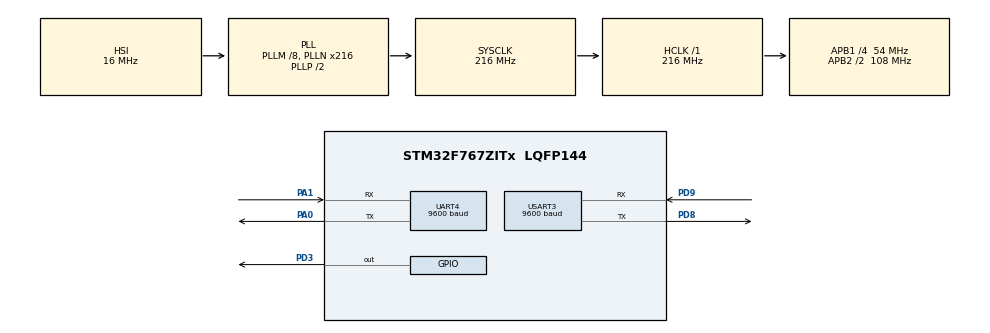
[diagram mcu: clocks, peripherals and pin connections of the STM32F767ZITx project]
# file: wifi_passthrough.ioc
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Mcu.Family=STM32F7
Mcu.Name=STM32F767ZITx
Mcu.Package=LQFP144
NVIC.PriorityGroup=NVIC_PRIORITYGROUP_4
NVIC.UART4_IRQn=true\:0\:0\:false\:false\:true\:true\:true
NVIC.USART3_IRQn=true\:0\:0\:false\:false\:true\:true\:true
PA0/WKUP.Mode=Asynchronous
PA0/WKUP.Signal=UART4_TX
PA1.Mode=Asynchronous
PA1.Signal=UART4_RX
PD3.Signal=GPIO_Output
PD8.Mode=Asynchronous
PD8.Signal=USART3_TX
PD9.Mode=Asynchronous
PD9.Signal=USART3_RX
ProjectManager.HeapSize=0x200
ProjectManager.StackSize=0x400
ProjectManager.TargetToolchain=MDK-ARM V5
RCC.48MHZClocksFreq_Value=24000000
RCC.AHBFreq_Value=216000000
RCC.APB1CLKDivider=RCC_HCLK_DIV4
RCC.APB1Freq_Value=54000000
RCC.APB1TimFreq_Value=108000000
RCC.APB2CLKDivider=RCC_HCLK_DIV2
RCC.APB2Freq_Value=108000000
RCC.APB2TimFreq_Value=216000000
RCC.CortexFreq_Value=216000000
RCC.HCLKFreq_Value=216000000
RCC.HSE_VALUE=16000000
RCC.HSI_VALUE=16000000
RCC.LSE_VALUE=32768
RCC.PLLM=8
RCC.PLLMUL=RCC_PLL_MUL9
RCC.PLLN=216
RCC.PRESCALERUSB=RCC_USBCLKSOURCE_PLL_DIV1_5
RCC.SYSCLKFreq_VALUE=216000000
RCC.SYSCLKSource=RCC_SYSCLKSOURCE_PLLCLK
RCC.SYSCLKSourceVirtual=RCC_SYSCLKSOURCE_PLLCLK
RCC.USBFreq_Value=216000000
RCC.VCOOutputFreq_Value=432000000
UART4.BaudRate=9600
USART3.BaudRate=9600
USART3.VirtualMode-Asynchronous=VM_ASYNC
board=NUCLEO-F767ZI

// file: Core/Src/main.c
/* USER CODE BEGIN Header */
/**
  ******************************************************************************
  * @file           : main.c
  * @brief          : Main program body
  ******************************************************************************
  * @attention
  *
  * <h2><center>&copy; Copyright (c) 2020 STMicroelectronics.
  * All rights reserved.</center></h2>
  *
  * This software component is licensed by ST under BSD 3-Clause license,
  * the "License"; You may not use this file except in compliance with the
  * License. You may obtain a copy of the License at:
  *                        opensource.org/licenses/BSD-3-Clause
  *
  ******************************************************************************
  */
/* USER CODE END Header */

#include "main.h"
#include "usart.h"
#include "gpio.h"

void SystemClock_Config(void);

int main(void)
{

  /* MCU Configuration--------------------------------------------------------*/

  /* Reset of all peripherals, Initializes the Flash interface and the Systick. */
  HAL_Init();

  /* Configure the system clock */
  SystemClock_Config();

  /* Initialize all configured peripherals */
  MX_GPIO_Init();
  MX_UART4_Init();
  MX_USART3_UART_Init();
  /* USER CODE BEGIN 2 */

	HAL_GPIO_WritePin(GPIOD, GPIO_PIN_3, GPIO_PIN_RESET);

	HAL_UART_Receive_IT(&huart3, &buf3, 1);
	HAL_UART_Receive_IT(&huart4, &buf4, 1);

	HAL_Delay(200);
	HAL_GPIO_WritePin(GPIOD, GPIO_PIN_3, GPIO_PIN_SET);

  /* USER CODE END 2 */

  /* Infinite loop */
  while (1)
  {

  }
}

void SystemClock_Config(void)
{
  RCC_OscInitTypeDef RCC_OscInitStruct = {0};
  RCC_ClkInitTypeDef RCC_ClkInitStruct = {0};
  RCC_PeriphCLKInitTypeDef PeriphClkInitStruct = {0};

  /** Configure the main internal regulator output voltage
  */
  __HAL_RCC_PWR_CLK_ENABLE();
  __HAL_PWR_VOLTAGESCALING_CONFIG(PWR_REGULATOR_VOLTAGE_SCALE1);
  /** Initializes the CPU, AHB and APB busses clocks
  */
  RCC_OscInitStruct.OscillatorType = RCC_OSCILLATORTYPE_HSI;
  RCC_OscInitStruct.HSIState = RCC_HSI_ON;
  RCC_OscInitStruct.HSICalibrationValue = RCC_HSICALIBRATION_DEFAULT;
  RCC_OscInitStruct.PLL.PLLState = RCC_PLL_ON;
  RCC_OscInitStruct.PLL.PLLSource = RCC_PLLSOURCE_HSI;
  RCC_OscInitStruct.PLL.PLLM = 8;
  RCC_OscInitStruct.PLL.PLLN = 216;
  RCC_OscInitStruct.PLL.PLLP = RCC_PLLP_DIV2;
  RCC_OscInitStruct.PLL.PLLQ = 2;
  if (HAL_RCC_OscConfig(&RCC_OscInitStruct) != HAL_OK)
  {
    Error_Handler();
  }
  /** Activate the Over-Drive mode
  */
  if (HAL_PWREx_EnableOverDrive() != HAL_OK)
  {
    Error_Handler();
  }
  /** Initializes the CPU, AHB and APB busses clocks
  */
  RCC_ClkInitStruct.ClockType = RCC_CLOCKTYPE_HCLK|RCC_CLOCKTYPE_SYSCLK
                              |RCC_CLOCKTYPE_PCLK1|RCC_CLOCKTYPE_PCLK2;
  RCC_ClkInitStruct.SYSCLKSource = RCC_SYSCLKSOURCE_PLLCLK;
  RCC_ClkInitStruct.AHBCLKDivider = RCC_SYSCLK_DIV1;
  RCC_ClkInitStruct.APB1CLKDivider = RCC_HCLK_DIV4;
  RCC_ClkInitStruct.APB2CLKDivider = RCC_HCLK_DIV2;

  if (HAL_RCC_ClockConfig(&RCC_ClkInitStruct, FLASH_LATENCY_7) != HAL_OK)
  {
    Error_Handler();
  }
  PeriphClkInitStruct.PeriphClockSelection = RCC_PERIPHCLK_USART3|RCC_PERIPHCLK_UART4;
  PeriphClkInitStruct.Usart3ClockSelection = RCC_USART3CLKSOURCE_PCLK1;
  PeriphClkInitStruct.Uart4ClockSelection = RCC_UART4CLKSOURCE_PCLK1;
  if (HAL_RCCEx_PeriphCLKConfig(&PeriphClkInitStruct) != HAL_OK)
  {
    Error_Handler();
  }
}

void Error_Handler(void)
{
}

/************************ (C) COPYRIGHT STMicroelectronics *****END OF FILE****/
